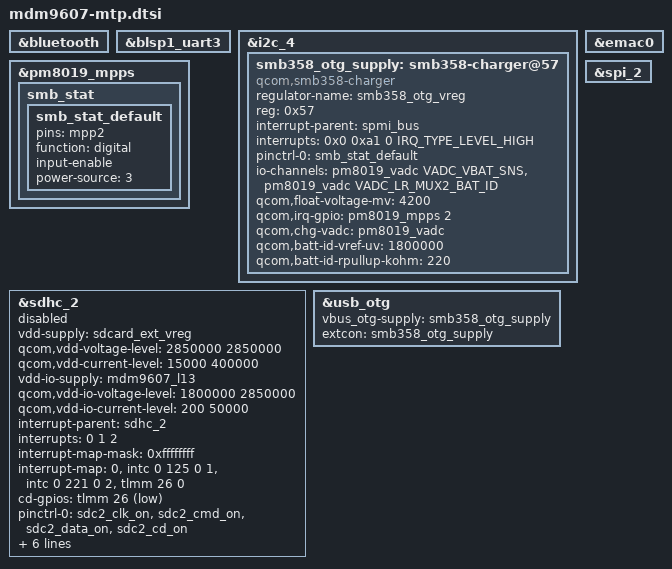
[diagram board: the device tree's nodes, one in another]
#include "mdm9607.dtsi"

&bluetooth {
	status = "ok";
};

&blsp1_uart3 {
	status = "ok";
};

&i2c_4 {
	status = "ok";
};

&pm8019_mpps {
	/* MPP 2 configs for SMB358 interrupt line */
	smb_stat {
		smb_stat_default: smb_stat_default {
			pins = "mpp2";
			function = "digital";
			input-enable;
			power-source = <3>;
		};
	};
};

&i2c_4 {
	/* SMB358 charger configuration */
	smb358_otg_supply: smb358-charger@57 {
		compatible = "qcom,smb358-charger";
		regulator-name = "smb358_otg_vreg";
		reg = <0x57>;
		interrupt-parent = <&spmi_bus>;
		interrupts = <0x0 0xa1 0 IRQ_TYPE_LEVEL_HIGH>;	/* PMIC MPP 2 */
		pinctrl-names = "default";
		pinctrl-0 = <&smb_stat_default>;
		io-channels = <&pm8019_vadc VADC_VBAT_SNS>,
		      <&pm8019_vadc VADC_LR_MUX2_BAT_ID>;
		io-channel-names = "vbat_sns",
				"batt_id_therm";
		qcom,float-voltage-mv = <4200>;
		qcom,irq-gpio = <&pm8019_mpps 2 0>;
		qcom,chg-vadc = <&pm8019_vadc>;
		qcom,batt-id-vref-uv = <1800000>;
		qcom,batt-id-rpullup-kohm = <220>;
	};
};

&emac0 {
	status = "ok";
};

&sdhc_2 {
	vdd-supply = <&sdcard_ext_vreg>;
	qcom,vdd-voltage-level = <2850000 2850000>;
	qcom,vdd-current-level = <15000 400000>;

	vdd-io-supply = <&mdm9607_l13>;
	qcom,vdd-io-voltage-level = <1800000 2850000>;
	qcom,vdd-io-current-level = <200 50000>;

	#address-cells = <0>;
	interrupt-parent = <&sdhc_2>;
	interrupts = <0 1 2>;
	#interrupt-cells = <1>;
	interrupt-map-mask = <0xffffffff>;
	interrupt-map = <0 &intc 0 125 0
			1 &intc 0 221 0
			2 &tlmm 26 0>;
	interrupt-names = "hc_irq", "pwr_irq", "status_irq";
	cd-gpios = <&tlmm 26 0x1>;

	pinctrl-names = "default", "sleep";
	pinctrl-0 = <&sdc2_clk_on &sdc2_cmd_on &sdc2_data_on &sdc2_cd_on>;
	pinctrl-1 = <&sdc2_clk_off &sdc2_cmd_off &sdc2_data_off>;

	qcom,nonremovable;
	keep-power-in-suspend;
	enable-sdio-wakeup;
	qcom,core_3_0v_support;
	status = "disabled";
};

&usb_otg {
	vbus_otg-supply = <&smb358_otg_supply>;
	extcon = <&smb358_otg_supply>;
};

&spi_2 {
	status = "ok";
};
